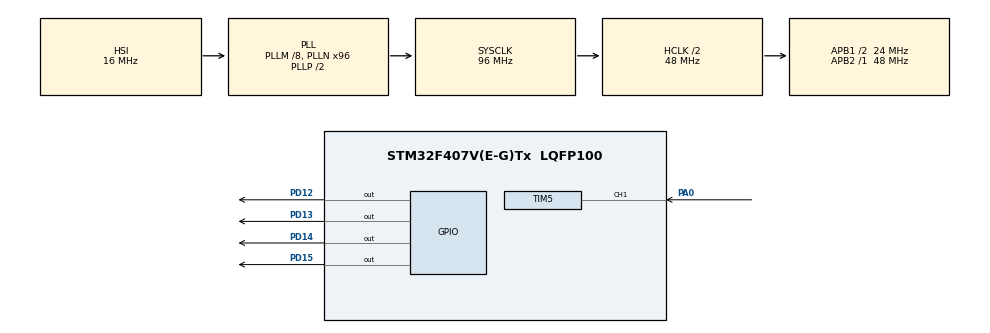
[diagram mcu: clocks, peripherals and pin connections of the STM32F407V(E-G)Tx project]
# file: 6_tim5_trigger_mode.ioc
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Mcu.Family=STM32F4
Mcu.Name=STM32F407V(E-G)Tx
Mcu.Package=LQFP100
NVIC.PriorityGroup=NVIC_PRIORITYGROUP_4
NVIC.TIM5_IRQn=true\:0\:0\:false\:false\:true\:true
PA0-WKUP.Signal=S_TIM5_CH1
PA13.Mode=Serial_Wire
PA13.Signal=SYS_JTMS-SWDIO
PA14.Mode=Serial_Wire
PA14.Signal=SYS_JTCK-SWCLK
PD12.Signal=GPIO_Output
PD13.Signal=GPIO_Output
PD14.Signal=GPIO_Output
PD15.Signal=GPIO_Output
ProjectManager.HeapSize=0x200
ProjectManager.StackSize=0x400
ProjectManager.TargetToolchain=MDK-ARM V5
RCC.48MHZClocksFreq_Value=48000000
RCC.AHBCLKDivider=RCC_SYSCLK_DIV2
RCC.AHBFreq_Value=48000000
RCC.APB1CLKDivider=RCC_HCLK_DIV2
RCC.APB1Freq_Value=24000000
RCC.APB1TimFreq_Value=48000000
RCC.APB2Freq_Value=48000000
RCC.APB2TimFreq_Value=48000000
RCC.CortexFreq_Value=48000000
RCC.HCLKFreq_Value=48000000
RCC.HSE_VALUE=25000000
RCC.HSI_VALUE=16000000
RCC.LSE_VALUE=32768
RCC.PLLM=8
RCC.PLLN=96
RCC.SYSCLKFreq_VALUE=96000000
RCC.SYSCLKSource=RCC_SYSCLKSOURCE_PLLCLK
RCC.VCOOutputFreq_Value=192000000
SH.S_TIM5_CH1.0=TIM5_CH1,TriggerSource_TI1FP1
TIM5.Period=499
TIM5.Prescaler=47999
TIM5.Slave_TriggerFilter=15
VP_TIM5_VS_ClockSourceINT.Mode=Internal
VP_TIM5_VS_ControllerModeTrigger.Mode=Trigger Mode
board=6_tim5_trigger_mode

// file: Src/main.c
/**
  ******************************************************************************
  * File Name          : main.c
  * Description        : Main program body
  ******************************************************************************
  ** This notice applies to any and all portions of this file
  * that are not between comment pairs USER CODE BEGIN and
  * USER CODE END. Other portions of this file, whether
  * inserted by the user or by software development tools
  * are owned by their respective copyright owners.
  *
  * COPYRIGHT(c) 2018 STMicroelectronics
  *
  * Redistribution and use in source and binary forms, with or without modification,
  * are permitted provided that the following conditions are met:
  *   1. Redistributions of source code must retain the above copyright notice,
  *      this list of conditions and the following disclaimer.
  *   2. Redistributions in binary form must reproduce the above copyright notice,
  *      this list of conditions and the following disclaimer in the documentation
  *      and/or other materials provided with the distribution.
  *   3. Neither the name of STMicroelectronics nor the names of its contributors
  *      may be used to endorse or promote products derived from this software
  *      without specific prior written permission.
  *
  * THIS SOFTWARE IS PROVIDED BY THE COPYRIGHT HOLDERS AND CONTRIBUTORS "AS IS"
  * AND ANY EXPRESS OR IMPLIED WARRANTIES, INCLUDING, BUT NOT LIMITED TO, THE
  * IMPLIED WARRANTIES OF MERCHANTABILITY AND FITNESS FOR A PARTICULAR PURPOSE ARE
  * DISCLAIMED. IN NO EVENT SHALL THE COPYRIGHT HOLDER OR CONTRIBUTORS BE LIABLE
  * FOR ANY DIRECT, INDIRECT, INCIDENTAL, SPECIAL, EXEMPLARY, OR CONSEQUENTIAL
  * DAMAGES (INCLUDING, BUT NOT LIMITED TO, PROCUREMENT OF SUBSTITUTE GOODS OR
  * SERVICES; LOSS OF USE, DATA, OR PROFITS; OR BUSINESS INTERRUPTION) HOWEVER
  * CAUSED AND ON ANY THEORY OF LIABILITY, WHETHER IN CONTRACT, STRICT LIABILITY,
  * OR TORT (INCLUDING NEGLIGENCE OR OTHERWISE) ARISING IN ANY WAY OUT OF THE USE
  * OF THIS SOFTWARE, EVEN IF ADVISED OF THE POSSIBILITY OF SUCH DAMAGE.
  *
  ******************************************************************************
  */
#include "main.h"
#include "stm32f4xx_hal.h"

/* USER CODE BEGIN Includes */
 uint32_t sayac_TIM5=0;
/* USER CODE END Includes */

TIM_HandleTypeDef htim5;

/* USER CODE BEGIN PV */
/* Private variables ---------------------------------------------------------*/

/* USER CODE END PV */

void SystemClock_Config(void);
static void MX_GPIO_Init(void);
static void MX_TIM5_Init(void);

/* USER CODE BEGIN PFP */
/* Private function prototypes -----------------------------------------------*/

/* USER CODE END PFP */
void HAL_TIM_PeriodElapsedCallback(TIM_HandleTypeDef *htim)
{

  if( htim->Instance==TIM5)
	{

		HAL_GPIO_TogglePin(GPIOD,GPIO_PIN_13);

	}

}

int main(void)
{

  /* MCU Configuration----------------------------------------------------------*/

  /* Reset of all peripherals, Initializes the Flash interface and the Systick. */
  HAL_Init();

  /* Configure the system clock */
  SystemClock_Config();

  /* Initialize all configured peripherals */
  MX_GPIO_Init();
  MX_TIM5_Init();

 /*slave mode de trigger mode seçili suan.
 HAL_TIM_Base_Start_IT(&htim5);
bunu iptal etme sebebimiz triggerda tetikleme geldiginde
timer baslatilmis oluyor zati ekstradan yazmaya gerek yok
 ama normal mod çalisir interrupt aktif etmek için koda
 eklEma yapmak lazim update event ini  aktif edelim.*/

  __HAL_TIM_CLEAR_FLAG(&htim5,TIM_FLAG_UPDATE);

  /* Infinite loop */
  while (1)
  {
       sayac_TIM5=__HAL_TIM_GetCounter(&htim5);

		while(__HAL_TIM_GET_FLAG(&htim5,TIM_FLAG_TRIGGER) !=RESET)
		{
		  HAL_GPIO_TogglePin(GPIOD,GPIO_PIN_12);
			__HAL_TIM_ENABLE_IT(&htim5,TIM_IT_UPDATE); // update flag ini aktif ettik.
			__HAL_TIM_CLEAR_FLAG(&htim5,TIM_FLAG_TRIGGER);

		}

  }

}

/** System Clock Configuration
*/
void SystemClock_Config(void)
{

  RCC_OscInitTypeDef RCC_OscInitStruct;
  RCC_ClkInitTypeDef RCC_ClkInitStruct;

    /**Configure the main internal regulator output voltage
    */
  __HAL_RCC_PWR_CLK_ENABLE();

  __HAL_PWR_VOLTAGESCALING_CONFIG(PWR_REGULATOR_VOLTAGE_SCALE1);

    /**Initializes the CPU, AHB and APB busses clocks
    */
  RCC_OscInitStruct.OscillatorType = RCC_OSCILLATORTYPE_HSI;
  RCC_OscInitStruct.HSIState = RCC_HSI_ON;
  RCC_OscInitStruct.HSICalibrationValue = 16;
  RCC_OscInitStruct.PLL.PLLState = RCC_PLL_ON;
  RCC_OscInitStruct.PLL.PLLSource = RCC_PLLSOURCE_HSI;
  RCC_OscInitStruct.PLL.PLLM = 8;
  RCC_OscInitStruct.PLL.PLLN = 96;
  RCC_OscInitStruct.PLL.PLLP = RCC_PLLP_DIV2;
  RCC_OscInitStruct.PLL.PLLQ = 4;
  if (HAL_RCC_OscConfig(&RCC_OscInitStruct) != HAL_OK)
  {
    _Error_Handler(__FILE__, __LINE__);
  }

    /**Initializes the CPU, AHB and APB busses clocks
    */
  RCC_ClkInitStruct.ClockType = RCC_CLOCKTYPE_HCLK|RCC_CLOCKTYPE_SYSCLK
                              |RCC_CLOCKTYPE_PCLK1|RCC_CLOCKTYPE_PCLK2;
  RCC_ClkInitStruct.SYSCLKSource = RCC_SYSCLKSOURCE_PLLCLK;
  RCC_ClkInitStruct.AHBCLKDivider = RCC_SYSCLK_DIV2;
  RCC_ClkInitStruct.APB1CLKDivider = RCC_HCLK_DIV2;
  RCC_ClkInitStruct.APB2CLKDivider = RCC_HCLK_DIV1;

  if (HAL_RCC_ClockConfig(&RCC_ClkInitStruct, FLASH_LATENCY_1) != HAL_OK)
  {
    _Error_Handler(__FILE__, __LINE__);
  }

    /**Configure the Systick interrupt time
    */
  HAL_SYSTICK_Config(HAL_RCC_GetHCLKFreq()/1000);

    /**Configure the Systick
    */
  HAL_SYSTICK_CLKSourceConfig(SYSTICK_CLKSOURCE_HCLK);

  /* SysTick_IRQn interrupt configuration */
  HAL_NVIC_SetPriority(SysTick_IRQn, 0, 0);
}

/* TIM5 init function */
static void MX_TIM5_Init(void)
{

  TIM_ClockConfigTypeDef sClockSourceConfig;
  TIM_SlaveConfigTypeDef sSlaveConfig;
  TIM_MasterConfigTypeDef sMasterConfig;

  htim5.Instance = TIM5;
  htim5.Init.Prescaler = 47999;
  htim5.Init.CounterMode = TIM_COUNTERMODE_UP;
  htim5.Init.Period = 499;
  htim5.Init.ClockDivision = TIM_CLOCKDIVISION_DIV1;
  if (HAL_TIM_Base_Init(&htim5) != HAL_OK)
  {
    _Error_Handler(__FILE__, __LINE__);
  }

  sClockSourceConfig.ClockSource = TIM_CLOCKSOURCE_INTERNAL;
  if (HAL_TIM_ConfigClockSource(&htim5, &sClockSourceConfig) != HAL_OK)
  {
    _Error_Handler(__FILE__, __LINE__);
  }

  sSlaveConfig.SlaveMode = TIM_SLAVEMODE_TRIGGER;
  sSlaveConfig.InputTrigger = TIM_TS_TI1FP1;
  sSlaveConfig.TriggerPolarity = TIM_TRIGGERPOLARITY_RISING;
  sSlaveConfig.TriggerFilter = 15;
  if (HAL_TIM_SlaveConfigSynchronization(&htim5, &sSlaveConfig) != HAL_OK)
  {
    _Error_Handler(__FILE__, __LINE__);
  }

  sMasterConfig.MasterOutputTrigger = TIM_TRGO_RESET;
  sMasterConfig.MasterSlaveMode = TIM_MASTERSLAVEMODE_DISABLE;
  if (HAL_TIMEx_MasterConfigSynchronization(&htim5, &sMasterConfig) != HAL_OK)
  {
    _Error_Handler(__FILE__, __LINE__);
  }

}

/** Configure pins as
        * Analog
        * Input
        * Output
        * EVENT_OUT
        * EXTI
*/
static void MX_GPIO_Init(void)
{

  GPIO_InitTypeDef GPIO_InitStruct;

  /* GPIO Ports Clock Enable */
  __HAL_RCC_GPIOA_CLK_ENABLE();
  __HAL_RCC_GPIOD_CLK_ENABLE();

  /*Configure GPIO pin Output Level */
  HAL_GPIO_WritePin(GPIOD, GPIO_PIN_12|GPIO_PIN_13|GPIO_PIN_14|GPIO_PIN_15, GPIO_PIN_RESET);

  /*Configure GPIO pins : PD12 PD13 PD14 PD15 */
  GPIO_InitStruct.Pin = GPIO_PIN_12|GPIO_PIN_13|GPIO_PIN_14|GPIO_PIN_15;
  GPIO_InitStruct.Mode = GPIO_MODE_OUTPUT_PP;
  GPIO_InitStruct.Pull = GPIO_NOPULL;
  GPIO_InitStruct.Speed = GPIO_SPEED_FREQ_LOW;
  HAL_GPIO_Init(GPIOD, &GPIO_InitStruct);

}

void _Error_Handler(char * file, int line)
{
  while(1)
  {
  }
}

/************************ (C) COPYRIGHT STMicroelectronics *****END OF FILE****/
